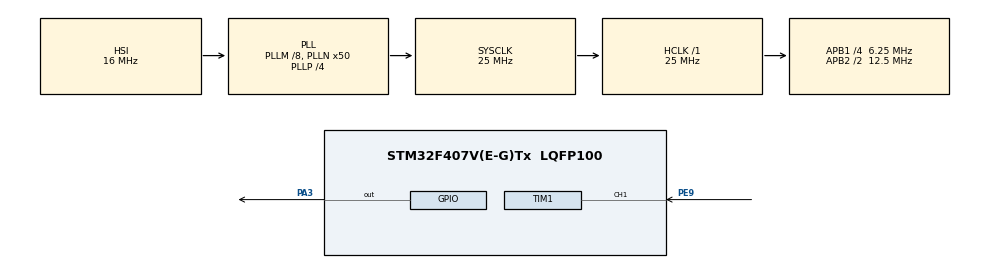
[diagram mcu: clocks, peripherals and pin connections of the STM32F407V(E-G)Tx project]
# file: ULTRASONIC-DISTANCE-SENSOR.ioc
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Mcu.Family=STM32F4
Mcu.Name=STM32F407V(E-G)Tx
Mcu.Package=LQFP100
NVIC.PriorityGroup=NVIC_PRIORITYGROUP_0
NVIC.TIM1_CC_IRQn=true\:0\:0\:false\:false\:true\:true\:true\:true
PA3.GPIO_Speed=GPIO_SPEED_FREQ_MEDIUM
PA3.Signal=GPIO_Output
PE9.GPIO_ModeDefaultPP=GPIO_MODE_AF_PP
PE9.Signal=S_TIM1_CH1
PH0-OSC_IN.Mode=HSE-External-Oscillator
PH0-OSC_IN.Signal=RCC_OSC_IN
PH1-OSC_OUT.Mode=HSE-External-Oscillator
PH1-OSC_OUT.Signal=RCC_OSC_OUT
ProjectManager.HeapSize=0x200
ProjectManager.StackSize=0x400
ProjectManager.TargetToolchain=STM32CubeIDE
RCC.48MHZClocksFreq_Value=14285714.285714285
RCC.AHBFreq_Value=25000000
RCC.APB1CLKDivider=RCC_HCLK_DIV4
RCC.APB1Freq_Value=6250000
RCC.APB1TimFreq_Value=12500000
RCC.APB2CLKDivider=RCC_HCLK_DIV2
RCC.APB2Freq_Value=12500000
RCC.APB2TimFreq_Value=25000000
RCC.CortexFreq_Value=25000000
RCC.HCLKFreq_Value=25000000
RCC.HSE_VALUE=8000000
RCC.HSI_VALUE=16000000
RCC.LSE_VALUE=32768
RCC.PLLM=8
RCC.PLLN=50
RCC.PLLP=RCC_PLLP_DIV4
RCC.PLLQ=7
RCC.SYSCLKFreq_VALUE=25000000
RCC.SYSCLKSource=RCC_SYSCLKSOURCE_PLLCLK
RCC.VCOOutputFreq_Value=100000000
SH.S_TIM1_CH1.0=TIM1_CH1,Input_Capture1_from_TI1
TIM1.Channel-Input_Capture1_from_TI1=TIM_CHANNEL_1
TIM1.ICPolarity_CH1=TIM_INPUTCHANNELPOLARITY_RISING
TIM1.Prescaler=24
VP_TIM1_VS_ClockSourceINT.Mode=Internal
board=STM32F407G-DISC1

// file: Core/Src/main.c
/* USER CODE BEGIN Header */
/**
  ******************************************************************************
  * @file           : main.c
  * @brief          : Main program body
  ******************************************************************************
  * @attention
  *
  * Copyright (c) 2025 STMicroelectronics.
  * All rights reserved.
  *
  * This software is licensed under terms that can be found in the LICENSE file
  * in the root directory of this software component.
  * If no LICENSE file comes with this software, it is provided AS-IS.
  *
  ******************************************************************************
  */
/* USER CODE END Header */
#include "main.h"

/* USER CODE BEGIN Includes */
#include <stdio.h>
/* USER CODE END Includes */

TIM_HandleTypeDef htim1;

/* USER CODE BEGIN PV */
GPIO_PinState state = 0;
uint32_t echo_state = 0;
uint32_t start_time = 0;
uint32_t stop_time = 0;
int distance = 0;
/* USER CODE END PV */

void SystemClock_Config(void);
static void MX_GPIO_Init(void);
static void MX_TIM1_Init(void);
/* USER CODE BEGIN PFP */
void sendTrig();

void delay(uint16_t time);

/* USER CODE END PFP */

int main(void)
{

  /* MCU Configuration--------------------------------------------------------*/

  /* Reset of all peripherals, Initializes the Flash interface and the Systick. */
  HAL_Init();

  /* Configure the system clock */
  SystemClock_Config();

  /* Initialize all configured peripherals */
  MX_GPIO_Init();
  MX_TIM1_Init();
  /* USER CODE BEGIN 2 */
  HAL_TIM_IC_Start_IT(&htim1, TIM_CHANNEL_1);

  /* USER CODE END 2 */

  /* Infinite loop */
  /* USER CODE BEGIN WHILE */
  while (1)
  {
	  printf("Distanta: %d \n", distance);
	  sendTrig();
	  HAL_Delay(50);
    /* USER CODE END WHILE */

  }
}

void SystemClock_Config(void)
{
  RCC_OscInitTypeDef RCC_OscInitStruct = {0};
  RCC_ClkInitTypeDef RCC_ClkInitStruct = {0};

  /** Configure the main internal regulator output voltage
  */
  __HAL_RCC_PWR_CLK_ENABLE();
  __HAL_PWR_VOLTAGESCALING_CONFIG(PWR_REGULATOR_VOLTAGE_SCALE1);

  /** Initializes the RCC Oscillators according to the specified parameters
  * in the RCC_OscInitTypeDef structure.
  */
  RCC_OscInitStruct.OscillatorType = RCC_OSCILLATORTYPE_HSI;
  RCC_OscInitStruct.HSIState = RCC_HSI_ON;
  RCC_OscInitStruct.HSICalibrationValue = RCC_HSICALIBRATION_DEFAULT;
  RCC_OscInitStruct.PLL.PLLState = RCC_PLL_ON;
  RCC_OscInitStruct.PLL.PLLSource = RCC_PLLSOURCE_HSI;
  RCC_OscInitStruct.PLL.PLLM = 8;
  RCC_OscInitStruct.PLL.PLLN = 50;
  RCC_OscInitStruct.PLL.PLLP = RCC_PLLP_DIV4;
  RCC_OscInitStruct.PLL.PLLQ = 7;
  if (HAL_RCC_OscConfig(&RCC_OscInitStruct) != HAL_OK)
  {
    Error_Handler();
  }

  /** Initializes the CPU, AHB and APB buses clocks
  */
  RCC_ClkInitStruct.ClockType = RCC_CLOCKTYPE_HCLK|RCC_CLOCKTYPE_SYSCLK
                              |RCC_CLOCKTYPE_PCLK1|RCC_CLOCKTYPE_PCLK2;
  RCC_ClkInitStruct.SYSCLKSource = RCC_SYSCLKSOURCE_PLLCLK;
  RCC_ClkInitStruct.AHBCLKDivider = RCC_SYSCLK_DIV1;
  RCC_ClkInitStruct.APB1CLKDivider = RCC_HCLK_DIV4;
  RCC_ClkInitStruct.APB2CLKDivider = RCC_HCLK_DIV2;

  if (HAL_RCC_ClockConfig(&RCC_ClkInitStruct, FLASH_LATENCY_0) != HAL_OK)
  {
    Error_Handler();
  }
}

static void MX_TIM1_Init(void)
{

  TIM_ClockConfigTypeDef sClockSourceConfig = {0};
  TIM_MasterConfigTypeDef sMasterConfig = {0};
  TIM_IC_InitTypeDef sConfigIC = {0};

  htim1.Instance = TIM1;
  htim1.Init.Prescaler = 24;
  htim1.Init.CounterMode = TIM_COUNTERMODE_UP;
  htim1.Init.Period = 65535;
  htim1.Init.ClockDivision = TIM_CLOCKDIVISION_DIV1;
  htim1.Init.RepetitionCounter = 0;
  htim1.Init.AutoReloadPreload = TIM_AUTORELOAD_PRELOAD_DISABLE;
  if (HAL_TIM_Base_Init(&htim1) != HAL_OK)
  {
    Error_Handler();
  }
  sClockSourceConfig.ClockSource = TIM_CLOCKSOURCE_INTERNAL;
  if (HAL_TIM_ConfigClockSource(&htim1, &sClockSourceConfig) != HAL_OK)
  {
    Error_Handler();
  }
  if (HAL_TIM_IC_Init(&htim1) != HAL_OK)
  {
    Error_Handler();
  }
  sMasterConfig.MasterOutputTrigger = TIM_TRGO_RESET;
  sMasterConfig.MasterSlaveMode = TIM_MASTERSLAVEMODE_DISABLE;
  if (HAL_TIMEx_MasterConfigSynchronization(&htim1, &sMasterConfig) != HAL_OK)
  {
    Error_Handler();
  }
  sConfigIC.ICPolarity = TIM_INPUTCHANNELPOLARITY_RISING;
  sConfigIC.ICSelection = TIM_ICSELECTION_DIRECTTI;
  sConfigIC.ICPrescaler = TIM_ICPSC_DIV1;
  sConfigIC.ICFilter = 0;
  if (HAL_TIM_IC_ConfigChannel(&htim1, &sConfigIC, TIM_CHANNEL_1) != HAL_OK)
  {
    Error_Handler();
  }

}

static void MX_GPIO_Init(void)
{
  GPIO_InitTypeDef GPIO_InitStruct = {0};

  /* GPIO Ports Clock Enable */
  __HAL_RCC_GPIOH_CLK_ENABLE();
  __HAL_RCC_GPIOA_CLK_ENABLE();
  __HAL_RCC_GPIOE_CLK_ENABLE();

  /*Configure GPIO pin Output Level */
  HAL_GPIO_WritePin(GPIOA, GPIO_PIN_3, GPIO_PIN_RESET);

  /*Configure GPIO pin : PA3 */
  GPIO_InitStruct.Pin = GPIO_PIN_3;
  GPIO_InitStruct.Mode = GPIO_MODE_OUTPUT_PP;
  GPIO_InitStruct.Pull = GPIO_NOPULL;
  GPIO_InitStruct.Speed = GPIO_SPEED_FREQ_MEDIUM;
  HAL_GPIO_Init(GPIOA, &GPIO_InitStruct);

}

/* USER CODE BEGIN 4 */

void delay(uint16_t time){
	__HAL_TIM_SET_COUNTER(&htim1, 0);
	while(__HAL_TIM_GET_COUNTER(&htim1) < time);
}

int _write(int file, char *ptr, int len)
{
  (void)file;
  int DataIdx;

  for (DataIdx = 0; DataIdx < len; DataIdx++)
  {
    ITM_SendChar(*ptr++);
  }
  return len;
}

void HAL_TIM_IC_CaptureCallback(TIM_HandleTypeDef *htim){

	if(htim->Instance == TIM1){

		if(echo_state == 0){
			start_time = HAL_TIM_ReadCapturedValue(&htim1, TIM_CHANNEL_1);
			__HAL_TIM_SET_CAPTUREPOLARITY(&htim1, TIM_CHANNEL_1, TIM_INPUTCHANNELPOLARITY_FALLING);
			echo_state = 1;
		}
		else{
			stop_time = HAL_TIM_ReadCapturedValue(&htim1, TIM_CHANNEL_1);

			uint32_t time;
			if (stop_time >= start_time)
				time = stop_time - start_time;
			else
				time = (htim->Instance->ARR - start_time + stop_time + 1);

			distance = (0.0343 * time) / 2;
			echo_state = 0;

			__HAL_TIM_SET_CAPTUREPOLARITY(&htim1, TIM_CHANNEL_1, TIM_INPUTCHANNELPOLARITY_RISING);
			__HAL_TIM_DISABLE_IT(&htim1, TIM_IT_CC1);
		}

	}
}

void sendTrig(){
	HAL_GPIO_WritePin(GPIOA, GPIO_PIN_3, GPIO_PIN_SET);
	state = HAL_GPIO_ReadPin(GPIOA, GPIO_PIN_3);
	delay(10);
	HAL_GPIO_WritePin(GPIOA, GPIO_PIN_3, GPIO_PIN_RESET);
	state = HAL_GPIO_ReadPin(GPIOA, GPIO_PIN_3);

	__HAL_TIM_ENABLE_IT(&htim1, TIM_IT_CC1);
}

/* USER CODE END 4 */

void Error_Handler(void)
{
  __disable_irq();
  while (1)
  {
  }
}
